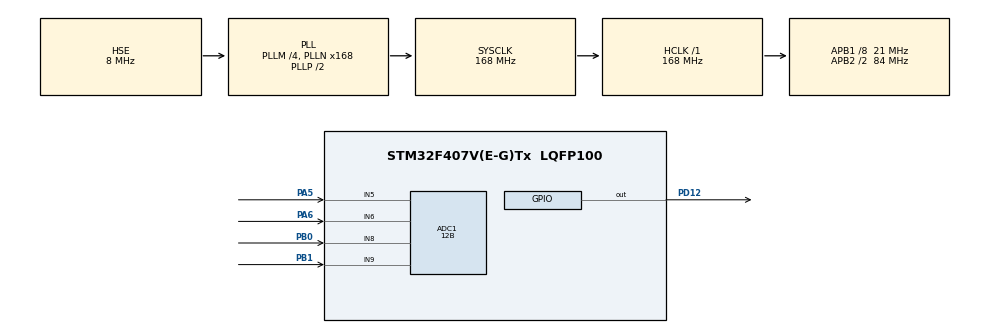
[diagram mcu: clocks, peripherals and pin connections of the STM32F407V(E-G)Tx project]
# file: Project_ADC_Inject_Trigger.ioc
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ADC1.Channel-0\#ChannelRegularConversion=ADC_CHANNEL_5
ADC1.Channel-1\#ChannelRegularConversion=ADC_CHANNEL_6
ADC1.Channel-2\#ChannelRegularConversion=ADC_CHANNEL_8
ADC1.Channel-3\#ChannelRegularConversion=ADC_CHANNEL_9
ADC1.Channel-4\#ChannelInjectedConversion=ADC_CHANNEL_5
ADC1.Channel-5\#ChannelInjectedConversion=ADC_CHANNEL_6
ADC1.Channel-6\#ChannelInjectedConversion=ADC_CHANNEL_8
ADC1.Channel-7\#ChannelInjectedConversion=ADC_CHANNEL_9
ADC1.ClockPrescaler=ADC_CLOCK_SYNC_PCLK_DIV4
ADC1.ContinuousConvMode=DISABLE
ADC1.DMAContinuousRequests=DISABLE
ADC1.DataAlign=ADC_DATAALIGN_RIGHT
ADC1.DiscontinuousConvMode=DISABLE
ADC1.EOCSelection=ADC_EOC_SEQ_CONV
ADC1.EnableAnalogWatchDog=false
ADC1.ExternalTrigConv=ADC_EXTERNALTRIGCONV_T2_TRGO
ADC1.ExternalTrigConvEdge=ADC_EXTERNALTRIGCONVEDGE_RISING
ADC1.ExternalTrigInjecConv=ADC_INJECTED_SOFTWARE_START
ADC1.ExternalTrigInjecConvEdge=ADC_EXTERNALTRIGINJECCONVEDGE_NONE
ADC1.InjNumberOfConversion=4
ADC1.InjectedConvMode=None
ADC1.InjectedOffset-4\#ChannelInjectedConversion=0
ADC1.InjectedOffset-5\#ChannelInjectedConversion=0
ADC1.InjectedOffset-6\#ChannelInjectedConversion=0
ADC1.InjectedOffset-7\#ChannelInjectedConversion=0
ADC1.NbrOfConversion=4
ADC1.NbrOfConversionFlag=1
ADC1.Rank-0\#ChannelRegularConversion=1
ADC1.Rank-1\#ChannelRegularConversion=2
ADC1.Rank-2\#ChannelRegularConversion=3
ADC1.Rank-3\#ChannelRegularConversion=4
ADC1.Rank-4\#ChannelInjectedConversion=1
ADC1.Rank-5\#ChannelInjectedConversion=2
ADC1.Rank-6\#ChannelInjectedConversion=3
ADC1.Rank-7\#ChannelInjectedConversion=4
ADC1.Resolution=ADC_RESOLUTION_12B
ADC1.SamplingTime-0\#ChannelRegularConversion=ADC_SAMPLETIME_3CYCLES
ADC1.SamplingTime-1\#ChannelRegularConversion=ADC_SAMPLETIME_3CYCLES
ADC1.SamplingTime-2\#ChannelRegularConversion=ADC_SAMPLETIME_3CYCLES
ADC1.SamplingTime-3\#ChannelRegularConversion=ADC_SAMPLETIME_3CYCLES
ADC1.SamplingTime-4\#ChannelInjectedConversion=ADC_SAMPLETIME_3CYCLES
ADC1.SamplingTime-5\#ChannelInjectedConversion=ADC_SAMPLETIME_3CYCLES
ADC1.SamplingTime-6\#ChannelInjectedConversion=ADC_SAMPLETIME_3CYCLES
ADC1.SamplingTime-7\#ChannelInjectedConversion=ADC_SAMPLETIME_3CYCLES
ADC1.ScanConvMode=ENABLE
ADC1.master=1
Mcu.Family=STM32F4
Mcu.Name=STM32F407V(E-G)Tx
Mcu.Package=LQFP100
NVIC.ADC_IRQn=true\:0\:0\:false\:false\:true\:true
NVIC.PriorityGroup=NVIC_PRIORITYGROUP_4
PA13.Mode=Serial_Wire
PA13.Signal=SYS_JTMS-SWDIO
PA14.Mode=Serial_Wire
PA14.Signal=SYS_JTCK-SWCLK
PA5.Signal=ADCx_IN5
PA6.Signal=ADCx_IN6
PB0.Signal=ADCx_IN8
PB1.Signal=ADCx_IN9
PD12.Signal=GPIO_Output
PH0-OSC_IN.Mode=HSE-External-Oscillator
PH0-OSC_IN.Signal=RCC_OSC_IN
PH1-OSC_OUT.Mode=HSE-External-Oscillator
PH1-OSC_OUT.Signal=RCC_OSC_OUT
ProjectManager.HeapSize=0x200
ProjectManager.StackSize=0x400
ProjectManager.TargetToolchain=MDK-ARM V5
RCC.48MHZClocksFreq_Value=84000000
RCC.AHBFreq_Value=168000000
RCC.APB1CLKDivider=RCC_HCLK_DIV8
RCC.APB1Freq_Value=21000000
RCC.APB1TimFreq_Value=42000000
RCC.APB2CLKDivider=RCC_HCLK_DIV2
RCC.APB2Freq_Value=84000000
RCC.APB2TimFreq_Value=168000000
RCC.CortexFreq_Value=168000000
RCC.HCLKFreq_Value=168000000
RCC.HSE_VALUE=8000000
RCC.HSI_VALUE=16000000
RCC.LSE_VALUE=32768
RCC.PLLM=4
RCC.PLLN=168
RCC.PLLSourceVirtual=RCC_PLLSOURCE_HSE
RCC.SYSCLKFreq_VALUE=168000000
RCC.SYSCLKSource=RCC_SYSCLKSOURCE_PLLCLK
RCC.VCOOutputFreq_Value=336000000
SH.ADCx_IN5.0=ADC1_IN5,IN5
SH.ADCx_IN6.0=ADC1_IN6,IN6
SH.ADCx_IN8.0=ADC1_IN8,IN8
SH.ADCx_IN9.0=ADC1_IN9,IN9
TIM2.Period=3000
TIM2.Prescaler=20999
TIM2.TIM_MasterOutputTrigger=TIM_TRGO_UPDATE
VP_TIM2_VS_ClockSourceINT.Mode=Internal
board=Project_ADC_Inject_Trigger

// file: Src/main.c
/**
  ******************************************************************************
  * @file           : main.c
  * @brief          : Main program body
  ******************************************************************************
  ** This notice applies to any and all portions of this file
  * that are not between comment pairs USER CODE BEGIN and
  * USER CODE END. Other portions of this file, whether
  * inserted by the user or by software development tools
  * are owned by their respective copyright owners.
  *
  * COPYRIGHT(c) 2018 STMicroelectronics
  *
  * Redistribution and use in source and binary forms, with or without modification,
  * are permitted provided that the following conditions are met:
  *   1. Redistributions of source code must retain the above copyright notice,
  *      this list of conditions and the following disclaimer.
  *   2. Redistributions in binary form must reproduce the above copyright notice,
  *      this list of conditions and the following disclaimer in the documentation
  *      and/or other materials provided with the distribution.
  *   3. Neither the name of STMicroelectronics nor the names of its contributors
  *      may be used to endorse or promote products derived from this software
  *      without specific prior written permission.
  *
  * THIS SOFTWARE IS PROVIDED BY THE COPYRIGHT HOLDERS AND CONTRIBUTORS "AS IS"
  * AND ANY EXPRESS OR IMPLIED WARRANTIES, INCLUDING, BUT NOT LIMITED TO, THE
  * IMPLIED WARRANTIES OF MERCHANTABILITY AND FITNESS FOR A PARTICULAR PURPOSE ARE
  * DISCLAIMED. IN NO EVENT SHALL THE COPYRIGHT HOLDER OR CONTRIBUTORS BE LIABLE
  * FOR ANY DIRECT, INDIRECT, INCIDENTAL, SPECIAL, EXEMPLARY, OR CONSEQUENTIAL
  * DAMAGES (INCLUDING, BUT NOT LIMITED TO, PROCUREMENT OF SUBSTITUTE GOODS OR
  * SERVICES; LOSS OF USE, DATA, OR PROFITS; OR BUSINESS INTERRUPTION) HOWEVER
  * CAUSED AND ON ANY THEORY OF LIABILITY, WHETHER IN CONTRACT, STRICT LIABILITY,
  * OR TORT (INCLUDING NEGLIGENCE OR OTHERWISE) ARISING IN ANY WAY OUT OF THE USE
  * OF THIS SOFTWARE, EVEN IF ADVISED OF THE POSSIBILITY OF SUCH DAMAGE.
  *
  ******************************************************************************
  */
#include "main.h"
#include "stm32f4xx_hal.h"

/* USER CODE BEGIN Includes */
float u[4];
/* USER CODE END Includes */

ADC_HandleTypeDef hadc1;

TIM_HandleTypeDef htim2;

/* USER CODE BEGIN PV */
/* Private variables ---------------------------------------------------------*/

/* USER CODE END PV */

void SystemClock_Config(void);
static void MX_GPIO_Init(void);
static void MX_ADC1_Init(void);
static void MX_TIM2_Init(void);

/* USER CODE BEGIN PFP */
/* Private function prototypes -----------------------------------------------*/

/* USER CODE END PFP */

int main(void)
{

  /* MCU Configuration----------------------------------------------------------*/

  /* Reset of all peripherals, Initializes the Flash interface and the Systick. */
  HAL_Init();

  /* Configure the system clock */
  SystemClock_Config();

  /* Initialize all configured peripherals */
  MX_GPIO_Init();
  MX_ADC1_Init();
  MX_TIM2_Init();
  /* USER CODE BEGIN 2 */
	HAL_TIM_Base_Start_IT(&htim2);
  HAL_ADC_Start(&hadc1);
  /* USER CODE END 2 */

  /* Infinite loop */
  /* USER CODE BEGIN WHILE */
  while (1)
  {
		 u[0]=((float)HAL_ADC_GetValue(&hadc1))*3/4096;//занесём результат преобразований в переменную
  /* USER CODE END WHILE */

  }

}

void SystemClock_Config(void)
{

  RCC_OscInitTypeDef RCC_OscInitStruct;
  RCC_ClkInitTypeDef RCC_ClkInitStruct;

    /**Configure the main internal regulator output voltage
    */
  __HAL_RCC_PWR_CLK_ENABLE();

  __HAL_PWR_VOLTAGESCALING_CONFIG(PWR_REGULATOR_VOLTAGE_SCALE1);

    /**Initializes the CPU, AHB and APB busses clocks
    */
  RCC_OscInitStruct.OscillatorType = RCC_OSCILLATORTYPE_HSE;
  RCC_OscInitStruct.HSEState = RCC_HSE_ON;
  RCC_OscInitStruct.PLL.PLLState = RCC_PLL_ON;
  RCC_OscInitStruct.PLL.PLLSource = RCC_PLLSOURCE_HSE;
  RCC_OscInitStruct.PLL.PLLM = 4;
  RCC_OscInitStruct.PLL.PLLN = 168;
  RCC_OscInitStruct.PLL.PLLP = RCC_PLLP_DIV2;
  RCC_OscInitStruct.PLL.PLLQ = 4;
  if (HAL_RCC_OscConfig(&RCC_OscInitStruct) != HAL_OK)
  {
    _Error_Handler(__FILE__, __LINE__);
  }

    /**Initializes the CPU, AHB and APB busses clocks
    */
  RCC_ClkInitStruct.ClockType = RCC_CLOCKTYPE_HCLK|RCC_CLOCKTYPE_SYSCLK
                              |RCC_CLOCKTYPE_PCLK1|RCC_CLOCKTYPE_PCLK2;
  RCC_ClkInitStruct.SYSCLKSource = RCC_SYSCLKSOURCE_PLLCLK;
  RCC_ClkInitStruct.AHBCLKDivider = RCC_SYSCLK_DIV1;
  RCC_ClkInitStruct.APB1CLKDivider = RCC_HCLK_DIV8;
  RCC_ClkInitStruct.APB2CLKDivider = RCC_HCLK_DIV2;

  if (HAL_RCC_ClockConfig(&RCC_ClkInitStruct, FLASH_LATENCY_5) != HAL_OK)
  {
    _Error_Handler(__FILE__, __LINE__);
  }

    /**Configure the Systick interrupt time
    */
  HAL_SYSTICK_Config(HAL_RCC_GetHCLKFreq()/1000);

    /**Configure the Systick
    */
  HAL_SYSTICK_CLKSourceConfig(SYSTICK_CLKSOURCE_HCLK);

  /* SysTick_IRQn interrupt configuration */
  HAL_NVIC_SetPriority(SysTick_IRQn, 0, 0);
}

/* ADC1 init function */
static void MX_ADC1_Init(void)
{

  ADC_ChannelConfTypeDef sConfig;
  ADC_InjectionConfTypeDef sConfigInjected;

    /**Configure the global features of the ADC (Clock, Resolution, Data Alignment and number of conversion)
    */
  hadc1.Instance = ADC1;
  hadc1.Init.ClockPrescaler = ADC_CLOCK_SYNC_PCLK_DIV4;
  hadc1.Init.Resolution = ADC_RESOLUTION_12B;
  hadc1.Init.ScanConvMode = ENABLE;
  hadc1.Init.ContinuousConvMode = DISABLE;
  hadc1.Init.DiscontinuousConvMode = DISABLE;
  hadc1.Init.ExternalTrigConvEdge = ADC_EXTERNALTRIGCONVEDGE_RISING;
  hadc1.Init.ExternalTrigConv = ADC_EXTERNALTRIGCONV_T2_TRGO;
  hadc1.Init.DataAlign = ADC_DATAALIGN_RIGHT;
  hadc1.Init.NbrOfConversion = 4;
  hadc1.Init.DMAContinuousRequests = DISABLE;
  hadc1.Init.EOCSelection = ADC_EOC_SEQ_CONV;
  if (HAL_ADC_Init(&hadc1) != HAL_OK)
  {
    _Error_Handler(__FILE__, __LINE__);
  }

    /**Configure for the selected ADC regular channel its corresponding rank in the sequencer and its sample time.
    */
  sConfig.Channel = ADC_CHANNEL_5;
  sConfig.Rank = 1;
  sConfig.SamplingTime = ADC_SAMPLETIME_3CYCLES;
  if (HAL_ADC_ConfigChannel(&hadc1, &sConfig) != HAL_OK)
  {
    _Error_Handler(__FILE__, __LINE__);
  }

    /**Configure for the selected ADC regular channel its corresponding rank in the sequencer and its sample time.
    */
  sConfig.Channel = ADC_CHANNEL_6;
  sConfig.Rank = 2;
  if (HAL_ADC_ConfigChannel(&hadc1, &sConfig) != HAL_OK)
  {
    _Error_Handler(__FILE__, __LINE__);
  }

    /**Configure for the selected ADC regular channel its corresponding rank in the sequencer and its sample time.
    */
  sConfig.Channel = ADC_CHANNEL_8;
  sConfig.Rank = 3;
  if (HAL_ADC_ConfigChannel(&hadc1, &sConfig) != HAL_OK)
  {
    _Error_Handler(__FILE__, __LINE__);
  }

    /**Configure for the selected ADC regular channel its corresponding rank in the sequencer and its sample time.
    */
  sConfig.Channel = ADC_CHANNEL_9;
  sConfig.Rank = 4;
  if (HAL_ADC_ConfigChannel(&hadc1, &sConfig) != HAL_OK)
  {
    _Error_Handler(__FILE__, __LINE__);
  }

    /**Configures for the selected ADC injected channel its corresponding rank in the sequencer and its sample time
    */
  sConfigInjected.InjectedChannel = ADC_CHANNEL_5;
  sConfigInjected.InjectedRank = 1;
  sConfigInjected.InjectedNbrOfConversion = 4;
  sConfigInjected.InjectedSamplingTime = ADC_SAMPLETIME_3CYCLES;
  sConfigInjected.ExternalTrigInjecConvEdge = ADC_EXTERNALTRIGINJECCONVEDGE_NONE;
  sConfigInjected.ExternalTrigInjecConv = ADC_INJECTED_SOFTWARE_START;
  sConfigInjected.AutoInjectedConv = DISABLE;
  sConfigInjected.InjectedDiscontinuousConvMode = DISABLE;
  sConfigInjected.InjectedOffset = 0;
  if (HAL_ADCEx_InjectedConfigChannel(&hadc1, &sConfigInjected) != HAL_OK)
  {
    _Error_Handler(__FILE__, __LINE__);
  }

    /**Configures for the selected ADC injected channel its corresponding rank in the sequencer and its sample time
    */
  sConfigInjected.InjectedChannel = ADC_CHANNEL_6;
  sConfigInjected.InjectedRank = 2;
  if (HAL_ADCEx_InjectedConfigChannel(&hadc1, &sConfigInjected) != HAL_OK)
  {
    _Error_Handler(__FILE__, __LINE__);
  }

    /**Configures for the selected ADC injected channel its corresponding rank in the sequencer and its sample time
    */
  sConfigInjected.InjectedChannel = ADC_CHANNEL_8;
  sConfigInjected.InjectedRank = 3;
  if (HAL_ADCEx_InjectedConfigChannel(&hadc1, &sConfigInjected) != HAL_OK)
  {
    _Error_Handler(__FILE__, __LINE__);
  }

    /**Configures for the selected ADC injected channel its corresponding rank in the sequencer and its sample time
    */
  sConfigInjected.InjectedChannel = ADC_CHANNEL_9;
  sConfigInjected.InjectedRank = 4;
  if (HAL_ADCEx_InjectedConfigChannel(&hadc1, &sConfigInjected) != HAL_OK)
  {
    _Error_Handler(__FILE__, __LINE__);
  }

}

/* TIM2 init function */
static void MX_TIM2_Init(void)
{

  TIM_ClockConfigTypeDef sClockSourceConfig;
  TIM_MasterConfigTypeDef sMasterConfig;

  htim2.Instance = TIM2;
  htim2.Init.Prescaler = 20999;
  htim2.Init.CounterMode = TIM_COUNTERMODE_UP;
  htim2.Init.Period = 3000;
  htim2.Init.ClockDivision = TIM_CLOCKDIVISION_DIV1;
  if (HAL_TIM_Base_Init(&htim2) != HAL_OK)
  {
    _Error_Handler(__FILE__, __LINE__);
  }

  sClockSourceConfig.ClockSource = TIM_CLOCKSOURCE_INTERNAL;
  if (HAL_TIM_ConfigClockSource(&htim2, &sClockSourceConfig) != HAL_OK)
  {
    _Error_Handler(__FILE__, __LINE__);
  }

  sMasterConfig.MasterOutputTrigger = TIM_TRGO_UPDATE;
  sMasterConfig.MasterSlaveMode = TIM_MASTERSLAVEMODE_DISABLE;
  if (HAL_TIMEx_MasterConfigSynchronization(&htim2, &sMasterConfig) != HAL_OK)
  {
    _Error_Handler(__FILE__, __LINE__);
  }

}

/** Configure pins as
        * Analog
        * Input
        * Output
        * EVENT_OUT
        * EXTI
*/
static void MX_GPIO_Init(void)
{

  GPIO_InitTypeDef GPIO_InitStruct;

  /* GPIO Ports Clock Enable */
  __HAL_RCC_GPIOH_CLK_ENABLE();
  __HAL_RCC_GPIOA_CLK_ENABLE();
  __HAL_RCC_GPIOB_CLK_ENABLE();
  __HAL_RCC_GPIOD_CLK_ENABLE();

  /*Configure GPIO pin Output Level */
  HAL_GPIO_WritePin(GPIOD, GPIO_PIN_12, GPIO_PIN_RESET);

  /*Configure GPIO pin : PD12 */
  GPIO_InitStruct.Pin = GPIO_PIN_12;
  GPIO_InitStruct.Mode = GPIO_MODE_OUTPUT_PP;
  GPIO_InitStruct.Pull = GPIO_NOPULL;
  GPIO_InitStruct.Speed = GPIO_SPEED_FREQ_LOW;
  HAL_GPIO_Init(GPIOD, &GPIO_InitStruct);

}

/* USER CODE BEGIN 4 */
void HAL_TIM_PeriodElapsedCallback(TIM_HandleTypeDef *htim2)
{
  HAL_GPIO_TogglePin(GPIOD, GPIO_PIN_12);
}
/* USER CODE END 4 */

void _Error_Handler(char *file, int line)
{
  while(1)
  {
  }
}

/************************ (C) COPYRIGHT STMicroelectronics *****END OF FILE****/
